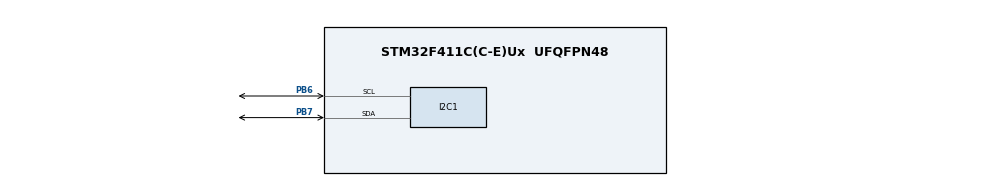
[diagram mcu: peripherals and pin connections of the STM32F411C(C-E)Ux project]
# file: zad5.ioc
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Mcu.Family=STM32F4
Mcu.Name=STM32F411C(C-E)Ux
Mcu.Package=UFQFPN48
NVIC.I2C1_EV_IRQn=true\:0\:0\:false\:false\:true\:true\:true\:true
NVIC.PriorityGroup=NVIC_PRIORITYGROUP_4
PB6.Mode=I2C
PB6.Signal=I2C1_SCL
PB7.Mode=I2C
PB7.Signal=I2C1_SDA
ProjectManager.HeapSize=0x200
ProjectManager.StackSize=0x400
ProjectManager.TargetToolchain=STM32CubeIDE
RCC.AHBFreq_Value=16000000
RCC.APB1Freq_Value=16000000
RCC.APB2Freq_Value=16000000
RCC.CortexFreq_Value=16000000
RCC.HSE_VALUE=25000000
RCC.HSI_VALUE=16000000
RCC.LSE_VALUE=32768
RCC.SYSCLKFreq_VALUE=16000000
RCC.VCOOutputFreq_Value=192000000
board=custom

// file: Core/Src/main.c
/* USER CODE BEGIN Header */
/**
  ******************************************************************************
  * @file           : main.c
  * @brief          : Main program body
  ******************************************************************************
  * @attention
  *
  * Copyright (c) 2025 STMicroelectronics.
  * All rights reserved.
  *
  * This software is licensed under terms that can be found in the LICENSE file
  * in the root directory of this software component.
  * If no LICENSE file comes with this software, it is provided AS-IS.
  *
  ******************************************************************************
  */
/* USER CODE END Header */
#include "main.h"
#include "i2c.h"
#include "gpio.h"

/* USER CODE BEGIN PD */
#define 	LSM6DS0_DEVICE_ADDRESS		0xD6U
#define 	LSM6DS0_WHO_AM_I_VALUE		0x68U
#define 	LSM6DS0_WHO_AM_I_ADDRES		0x0FU
/* USER CODE END PD */

void SystemClock_Config(void);

int main(void)
{

  /* MCU Configuration--------------------------------------------------------*/

  /* Reset of all peripherals, Initializes the Flash interface and the Systick. */
  LL_APB2_GRP1_EnableClock(LL_APB2_GRP1_PERIPH_SYSCFG);
  LL_APB1_GRP1_EnableClock(LL_APB1_GRP1_PERIPH_PWR);

  /* System interrupt init*/
  NVIC_SetPriorityGrouping(NVIC_PRIORITYGROUP_4);

  /* SysTick_IRQn interrupt configuration */
  NVIC_SetPriority(SysTick_IRQn, NVIC_EncodePriority(NVIC_GetPriorityGrouping(),15, 0));

  /* Configure the system clock */
  SystemClock_Config();

  /* Initialize all configured peripherals */
  MX_GPIO_Init();
  MX_I2C1_Init();

  /* Infinite loop */
  while (1)
  {

  }
}

void SystemClock_Config(void)
{
  LL_FLASH_SetLatency(LL_FLASH_LATENCY_0);
  while(LL_FLASH_GetLatency()!= LL_FLASH_LATENCY_0)
  {
  }
  LL_PWR_SetRegulVoltageScaling(LL_PWR_REGU_VOLTAGE_SCALE1);
  LL_RCC_HSI_SetCalibTrimming(16);
  LL_RCC_HSI_Enable();

   /* Wait till HSI is ready */
  while(LL_RCC_HSI_IsReady() != 1)
  {

  }
  LL_RCC_SetAHBPrescaler(LL_RCC_SYSCLK_DIV_1);
  LL_RCC_SetAPB1Prescaler(LL_RCC_APB1_DIV_1);
  LL_RCC_SetAPB2Prescaler(LL_RCC_APB2_DIV_1);
  LL_RCC_SetSysClkSource(LL_RCC_SYS_CLKSOURCE_HSI);

   /* Wait till System clock is ready */
  while(LL_RCC_GetSysClkSource() != LL_RCC_SYS_CLKSOURCE_STATUS_HSI)
  {

  }
  LL_Init1msTick(16000000);
  LL_SetSystemCoreClock(16000000);
  LL_RCC_SetTIMPrescaler(LL_RCC_TIM_PRESCALER_TWICE);
}

void Error_Handler(void)
{
  __disable_irq();
  while (1)
  {
  }
}
